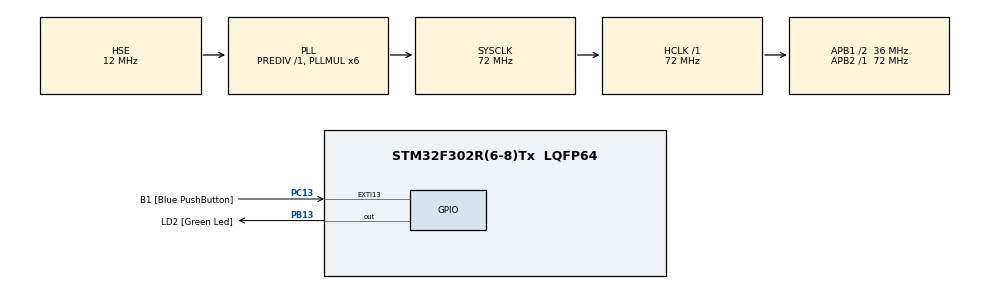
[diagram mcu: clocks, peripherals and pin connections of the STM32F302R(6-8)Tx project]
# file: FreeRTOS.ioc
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FREERTOS.Tasks01=defaultTask,0,128,StartDefaultTask,Default,NULL,Dynamic,NULL,NULL
Mcu.Family=STM32F3
Mcu.Name=STM32F302R(6-8)Tx
Mcu.Package=LQFP64
NVIC.PriorityGroup=NVIC_PRIORITYGROUP_4
PB13.GPIO_Label=LD2 [Green Led]
PB13.Signal=GPIO_Output
PC13.GPIO_Label=B1 [Blue PushButton]
PC13.GPIO_ModeDefaultEXTI=GPIO_MODE_IT_FALLING
PC13.Signal=GPXTI13
PF0-OSC_IN.Mode=HSE-External-Oscillator
PF0-OSC_IN.Signal=RCC_OSC_IN
PF1-OSC_OUT.Mode=HSE-External-Oscillator
PF1-OSC_OUT.Signal=RCC_OSC_OUT
ProjectManager.HeapSize=0x200
ProjectManager.StackSize=0x400
ProjectManager.TargetToolchain=STM32CubeIDE
RCC.AHBFreq_Value=72000000
RCC.APB1CLKDivider=RCC_HCLK_DIV2
RCC.APB1Freq_Value=36000000
RCC.APB1TimFreq_Value=72000000
RCC.APB2Freq_Value=72000000
RCC.APB2TimFreq_Value=72000000
RCC.CortexFreq_Value=72000000
RCC.HCLKFreq_Value=72000000
RCC.HSE_VALUE=12000000
RCC.HSI_VALUE=8000000
RCC.LSE_VALUE=32768
RCC.PLLM=8
RCC.PLLMUL=RCC_PLL_MUL6
RCC.PLLN=336
RCC.PLLP=RCC_PLLP_DIV4
RCC.PLLQ=7
RCC.PLLSourceVirtual=RCC_PLLSOURCE_HSE
RCC.SYSCLKFreq_VALUE=72000000
RCC.SYSCLKSourceVirtual=RCC_SYSCLKSOURCE_PLLCLK
RCC.USBFreq_Value=72000000
VP_FREERTOS_VS_CMSIS_V1.Mode=CMSIS_V1
board=NUCLEO-F302R8

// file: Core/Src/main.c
/* USER CODE BEGIN Header */
/**
  ******************************************************************************
  * @file           : main.c
  * @brief          : Main program body
  ******************************************************************************
  * @attention
  *
  * Copyright (c) 2025 STMicroelectronics.
  * All rights reserved.
  *
  * This software is licensed under terms that can be found in the LICENSE file
  * in the root directory of this software component.
  * If no LICENSE file comes with this software, it is provided AS-IS.
  *
  ******************************************************************************
  */
/* USER CODE END Header */
#include "main.h"
#include "cmsis_os.h"
#include "gpio.h"

/* USER CODE BEGIN Includes */
#include "FreeRTOS.h"
#include "task.h"
#include "SEGGER_SYSVIEW.h"
/* USER CODE END Includes */

/* USER CODE BEGIN PD */
#define DWT_CTRL *(volatile uint32_t*)0xE0001000
/* USER CODE END PD */

void SystemClock_Config(void);
void MX_FREERTOS_Init(void);

int main(void)
{

  /* MCU Configuration--------------------------------------------------------*/

  /* Reset of all peripherals, Initializes the Flash interface and the Systick. */
  HAL_Init();

  /* Configure the system clock */
  SystemClock_Config();

  /* Initialize all configured peripherals */
  MX_GPIO_Init();
  /* USER CODE BEGIN 2 */

  NVIC_SetPriorityGrouping( 0 );

  DWT_CTRL |= ( 1 << 0 );

  SEGGER_SYSVIEW_Conf();
  SEGGER_SYSVIEW_Start();

  /* USER CODE END 2 */

  /* Call init function for freertos objects (in cmsis_os2.c) */
  MX_FREERTOS_Init();

  /* Start scheduler */

  osKernelStart();

  /* We should never get here as control is now taken by the scheduler */

  /* Infinite loop */
  while (1)
  {

  }
}

void SystemClock_Config(void)
{
  RCC_OscInitTypeDef RCC_OscInitStruct = {0};
  RCC_ClkInitTypeDef RCC_ClkInitStruct = {0};

  /** Initializes the RCC Oscillators according to the specified parameters
  * in the RCC_OscInitTypeDef structure.
  */
  RCC_OscInitStruct.OscillatorType = RCC_OSCILLATORTYPE_HSE;
  RCC_OscInitStruct.HSEState = RCC_HSE_ON;
  RCC_OscInitStruct.HSEPredivValue = RCC_HSE_PREDIV_DIV1;
  RCC_OscInitStruct.HSIState = RCC_HSI_ON;
  RCC_OscInitStruct.PLL.PLLState = RCC_PLL_ON;
  RCC_OscInitStruct.PLL.PLLSource = RCC_PLLSOURCE_HSE;
  RCC_OscInitStruct.PLL.PLLMUL = RCC_PLL_MUL6;
  if (HAL_RCC_OscConfig(&RCC_OscInitStruct) != HAL_OK)
  {
    Error_Handler();
  }

  /** Initializes the CPU, AHB and APB buses clocks
  */
  RCC_ClkInitStruct.ClockType = RCC_CLOCKTYPE_HCLK|RCC_CLOCKTYPE_SYSCLK
                              |RCC_CLOCKTYPE_PCLK1|RCC_CLOCKTYPE_PCLK2;
  RCC_ClkInitStruct.SYSCLKSource = RCC_SYSCLKSOURCE_PLLCLK;
  RCC_ClkInitStruct.AHBCLKDivider = RCC_SYSCLK_DIV1;
  RCC_ClkInitStruct.APB1CLKDivider = RCC_HCLK_DIV2;
  RCC_ClkInitStruct.APB2CLKDivider = RCC_HCLK_DIV1;

  if (HAL_RCC_ClockConfig(&RCC_ClkInitStruct, FLASH_LATENCY_2) != HAL_OK)
  {
    Error_Handler();
  }
}

void Error_Handler(void)
{
  __disable_irq();
  while (1)
  {
  }
}

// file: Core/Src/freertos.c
/* USER CODE BEGIN Header */
/**
  ******************************************************************************
  * File Name          : freertos.c
  * Description        : Code for freertos applications
  ******************************************************************************
  * @attention
  *
  * Copyright (c) 2025 STMicroelectronics.
  * All rights reserved.
  *
  * This software is licensed under terms that can be found in the LICENSE file
  * in the root directory of this software component.
  * If no LICENSE file comes with this software, it is provided AS-IS.
  *
  ******************************************************************************
  */
/* USER CODE END Header */

#include "FreeRTOS.h"
#include "task.h"
#include "main.h"
#include "cmsis_os.h"

/* USER CODE BEGIN Includes */
#include <stdio.h>
/* USER CODE END Includes */

/* USER CODE BEGIN Variables */
TaskHandle_t handle_task1;
TaskHandle_t handle_task2;
/* USER CODE END Variables */
osThreadId defaultTaskHandle;

/* USER CODE BEGIN FunctionPrototypes */
static void task1(void*param);
static void task2(void*param);
/* USER CODE END FunctionPrototypes */

void StartDefaultTask(void const * argument);

void MX_FREERTOS_Init(void); /* (MISRA C 2004 rule 8.1) */

/* GetIdleTaskMemory prototype (linked to static allocation support) */
void vApplicationGetIdleTaskMemory( StaticTask_t **ppxIdleTaskTCBBuffer, StackType_t **ppxIdleTaskStackBuffer, uint32_t *pulIdleTaskStackSize );

/* USER CODE BEGIN GET_IDLE_TASK_MEMORY */
static StaticTask_t xIdleTaskTCBBuffer;
static StackType_t xIdleStack[configMINIMAL_STACK_SIZE];

void vApplicationGetIdleTaskMemory( StaticTask_t **ppxIdleTaskTCBBuffer, StackType_t **ppxIdleTaskStackBuffer, uint32_t *pulIdleTaskStackSize )
{
  *ppxIdleTaskTCBBuffer = &xIdleTaskTCBBuffer;
  *ppxIdleTaskStackBuffer = &xIdleStack[0];
  *pulIdleTaskStackSize = configMINIMAL_STACK_SIZE;
  /* place for user code */
}
/* USER CODE END GET_IDLE_TASK_MEMORY */

void MX_FREERTOS_Init(void) {

  /* Create the thread(s) */
  /* definition and creation of defaultTask */
  osThreadDef(defaultTask, StartDefaultTask, osPriorityNormal, 0, 128);
  defaultTaskHandle = osThreadCreate(osThread(defaultTask), NULL);

}

void StartDefaultTask(void const * argument)
{
  /* USER CODE BEGIN StartDefaultTask */
  /* Infinite loop */
	BaseType_t status;
	status = xTaskCreate(task1, "task1", 200, "Hello world task 1", 2, &handle_task1);

	configASSERT( status == pdPASS );

	status = xTaskCreate(task2, "task2", 200, "Hello world task 2", 2, &handle_task2);

	configASSERT( status == pdPASS );
  for(;;)
  {
    osDelay(1);
  }
  /* USER CODE END StartDefaultTask */
}

/* USER CODE BEGIN Application */
static void task1(void*param){

	while(1){
		printf("%s\n", (char*)param);
	}
}

static void task2(void*param){

	while(1){
		printf("%s\n", (char*)param);
	}
}
/* USER CODE END Application */
